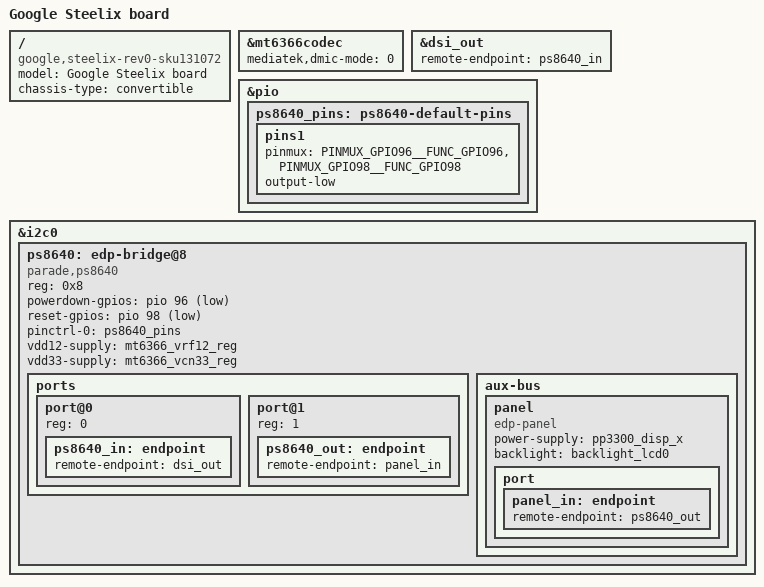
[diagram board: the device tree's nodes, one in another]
// SPDX-License-Identifier: (GPL-2.0 OR MIT)
/*
 * Copyright 2022 Google LLC
 */

/dts-v1/;
#include "mt8186-corsola-steelix.dtsi"

/ {
	model = "Google Steelix board";
	compatible = "google,steelix-rev0-sku131072", "google,steelix-rev1-sku131072",
		     "google,steelix-rev0", "google,steelix-rev1",
		     "google,steelix", "mediatek,mt8186";
	chassis-type = "convertible";
};

&mt6366codec {
	mediatek,dmic-mode = <0>; /* two-wire */
};

&dsi_out {
	remote-endpoint = <&ps8640_in>;
};

&pio {
	ps8640_pins: ps8640-default-pins {
		pins1 {
			pinmux = <PINMUX_GPIO96__FUNC_GPIO96>,
				<PINMUX_GPIO98__FUNC_GPIO98>;
			output-low;
		};
	};
};

&i2c0 {
	/delete-node/anx7625@58;

	ps8640: edp-bridge@8 {
		compatible = "parade,ps8640";
		reg = <0x8>;
		powerdown-gpios = <&pio 96 GPIO_ACTIVE_LOW>;
		reset-gpios = <&pio 98 GPIO_ACTIVE_LOW>;
		pinctrl-names = "default";
		pinctrl-0 = <&ps8640_pins>;
		vdd12-supply = <&mt6366_vrf12_reg>;
		vdd33-supply = <&mt6366_vcn33_reg>;

		ports {
			#address-cells = <1>;
			#size-cells = <0>;

			port@0 {
				reg = <0>;

				ps8640_in: endpoint {
					remote-endpoint = <&dsi_out>;
				};
			};

			port@1 {
				reg = <1>;

				ps8640_out: endpoint {
					remote-endpoint = <&panel_in>;
				};
			};
		};

		aux-bus {
			panel {
				compatible = "edp-panel";
				power-supply = <&pp3300_disp_x>;
				backlight = <&backlight_lcd0>;

				port {
					panel_in: endpoint {
						remote-endpoint = <&ps8640_out>;
					};
				};
			};
		};
	};
};
